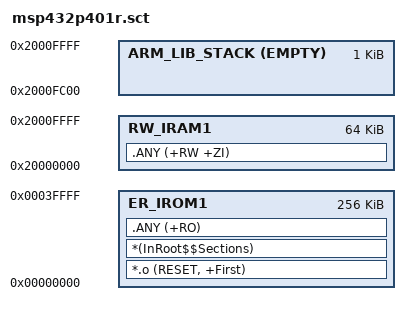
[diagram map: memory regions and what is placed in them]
#! armcc -E

/**********************************************************
 * ARM CC  linker script for Texas Instruments MSP432P401R
 **********************************************************/

/* Device specific values */

#define ROM_START   0x00000000
#define ROM_SIZE    0x00040000
#define RAM_START   0x20000000
#define RAM_SIZE    0x00010000
#define STACK_SIZE  0x00000400

/* Common - Do not change */

#if !defined(MBED_APP_START)
  #define MBED_APP_START ROM_START
#endif

#if !defined(MBED_APP_SIZE)
  #define MBED_APP_SIZE ROM_SIZE
#endif

LR_IROM1 MBED_APP_START MBED_APP_SIZE {

  ER_IROM1 MBED_APP_START MBED_APP_SIZE {
    *.o (RESET, +First)
    *(InRoot$$Sections)
    .ANY (+RO)
  }

  RW_IRAM1 RAM_START RAM_SIZE {
    .ANY (+RW +ZI)
  }

  ARM_LIB_STACK (RAM_START+RAM_SIZE) EMPTY -STACK_SIZE {
  }

}
